AUTOSAR XML (schema 4-0-3)
package /ComponentTypes
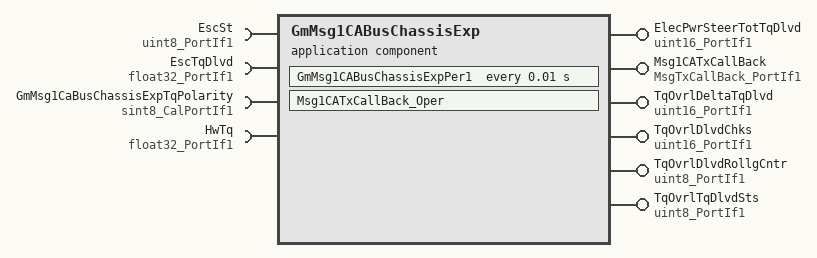
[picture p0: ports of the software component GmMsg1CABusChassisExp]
  application sw component type GmMsg1CABusChassisExp
    6 x provide port:
      ElecPwrSteerTotTqDlvd: nonqueued-sender-com-spec{data-element=Val, init-value=0}, provided-interface=uint16_PortIf1
      Msg1CATxCallBack: server-com-spec{operation=Oper, queue-length=1}, provided-interface=MsgTxCallBack_PortIf1
      TqOvrlDeltaTqDlvd: nonqueued-sender-com-spec{data-element=Val, init-value=0}, provided-interface=uint16_PortIf1
      TqOvrlDlvdChks: nonqueued-sender-com-spec{data-element=Val, init-value=0}, provided-interface=uint16_PortIf1
      TqOvrlDlvdRollgCntr: nonqueued-sender-com-spec{data-element=Val, init-value=0}, provided-interface=uint8_PortIf1
      TqOvrlTqDlvdSts: nonqueued-sender-com-spec{data-element=Val, init-value=0}, provided-interface=uint8_PortIf1
    4 x require port:
      EscSt: nonqueued-receiver-com-spec{data-element=Val, filter=data-filter-type=ALWAYS, init-value=0}, required-interface=uint8_PortIf1
      EscTqDlvd: nonqueued-receiver-com-spec{data-element=Val, filter=data-filter-type=ALWAYS, init-value=0}, required-interface=float32_PortIf1
      GmMsg1CaBusChassisExpTqPolarity: parameter-require-com-spec{init-value=1, parameter=Val}, required-interface=sint8_CalPortIf1
      HwTq: nonqueued-receiver-com-spec{data-element=Val, filter=data-filter-type=ALWAYS, init-value=0}, required-interface=float32_PortIf1
    behavior GmMsg1CABusChassisExp_InternalBehavior: data-type-mapping=Nexteer
      ar-typed-per-instance-memorys:
        data GmMsg1CABusChassisExpRollgCntr: sw-calibration-access=READ-ONLY, type=uint8
      timing event TMT_GM0C9HSPer1: start-on-event=GmMsg1CABusChassisExpPer1, period=0.01
      operation invoked event OIT_Msg1CATxCallBack_Oper_Msg1CATxCallBack_Oper: start-on-event=Msg1CATxCallBack_Oper, operation=Msg1CATxCallBack.Oper
      runnable GmMsg1CABusChassisExpPer1
        data-receive-point-by-arguments:
          access REC_EscSt_Val: accessed-variable=EscSt.Val
          access REC_EscTqDlvd_Val: accessed-variable=EscTqDlvd.Val
          access REC_HwTq_Val: accessed-variable=HwTq.Val
        data-send-points:
          5 x access:
            SEND_ElecPwrSteerTotTqDlvd_Val: accessed-variable=ElecPwrSteerTotTqDlvd.Val
            SEND_TqOvrlDeltaTqDlvd_Val: accessed-variable=TqOvrlDeltaTqDlvd.Val
            SEND_TqOvrlDlvdChks_Val: accessed-variable=TqOvrlDlvdChks.Val
            SEND_TqOvrlDlvdRollgCntr_Val: accessed-variable=TqOvrlDlvdRollgCntr.Val
            SEND_TqOvrlTqDlvdSts_Val: accessed-variable=TqOvrlTqDlvdSts.Val
      runnable Msg1CATxCallBack_Oper
  swc implementation GmMsg1CABusChassisExp_Implementation: behavior=GmMsg1CABusChassisExp_InternalBehavior
    code-descriptors:
      code Default: artifact-descriptors=autosar-engineering-object={short-label=Default, category=SWSRC}
